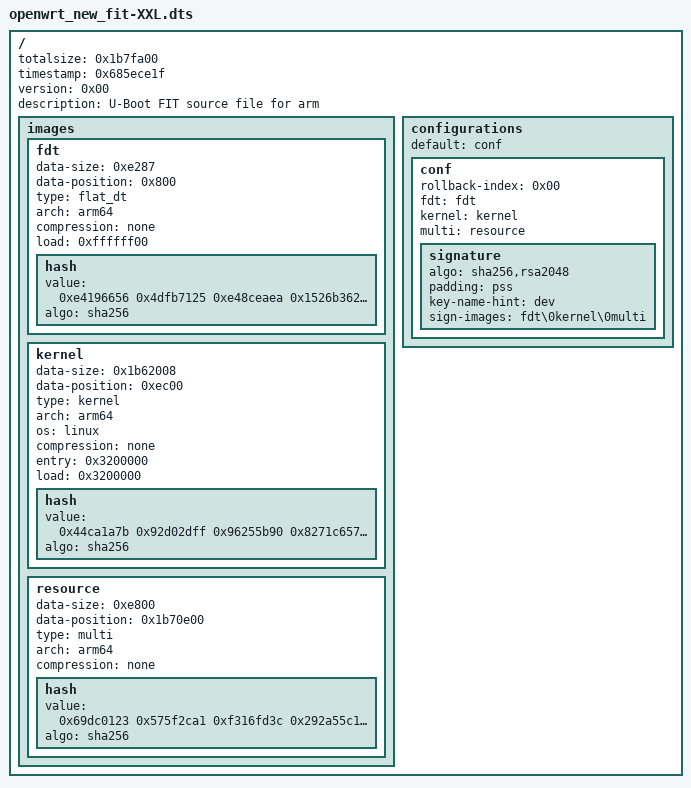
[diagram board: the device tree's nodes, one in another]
/dts-v1/;

/memreserve/	0x00007fcc57400000 0x0000000000000600;
/ {
	totalsize = <0x1b7fa00>;
	timestamp = <0x685ece1f>;
	version = <0x00>;
	description = "U-Boot FIT source file for arm";
	#address-cells = <0x01>;

	images {

		fdt {
			data-size = <0xe287>;
			data-position = <0x800>;
			type = "flat_dt";
			arch = "arm64";
			compression = "none";
			load = <0xffffff00>;

			hash {
				value = <0xe4196656 0x4dfb7125 0xe48ceaea 0x1526b362 0x1cb1d601 0xa8c68392 0x6c04ca2b 0xc01bc6b2>;
				algo = "sha256";
			};
		};

		kernel {
			data-size = <0x1b62008>;
			data-position = <0xec00>;
			type = "kernel";
			arch = "arm64";
			os = "linux";
			compression = "none";
			entry = <0x3200000>;
			load = <0x3200000>;

			hash {
				value = <0x44ca1a7b 0x92d02dff 0x96255b90 0x8271c657 0x894deaad 0x5ad1e351 0x85be1b 0xa80fc22f>;
				algo = "sha256";
			};
		};

		resource {
			data-size = <0xe800>;
			data-position = <0x1b70e00>;
			type = "multi";
			arch = "arm64";
			compression = "none";

			hash {
				value = <0x69dc0123 0x575f2ca1 0xf316fd3c 0x292a55c1 0x6df7c1e0 0xe5c88f9a 0x80ce1ce3 0x7ce0ddd9>;
				algo = "sha256";
			};
		};
	};

	configurations {
		default = "conf";

		conf {
			rollback-index = <0x00>;
			fdt = "fdt";
			kernel = "kernel";
			multi = "resource";

			signature {
				algo = "sha256,rsa2048";
				padding = "pss";
				key-name-hint = "dev";
				sign-images = "fdt\0kernel\0multi";
			};
		};
	};
};
